AUTOSAR XML (schema 4-2-2)
package /Components
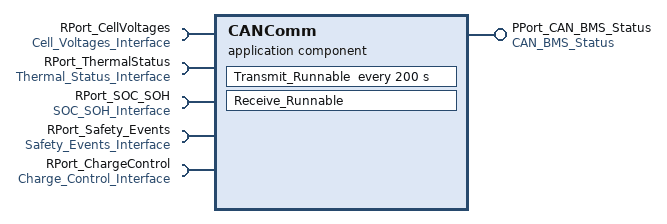
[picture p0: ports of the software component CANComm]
  application sw component type CANComm
    provide port PPort_CAN_BMS_Status: provided-interface=CAN_BMS_Status
    5 x require port:
      RPort_CellVoltages: required-interface=Cell_Voltages_Interface
      RPort_ThermalStatus: required-interface=Thermal_Status_Interface
      RPort_SOC_SOH: required-interface=SOC_SOH_Interface
      RPort_Safety_Events: required-interface=Safety_Events_Interface
      RPort_ChargeControl: required-interface=Charge_Control_Interface
    behavior CANComm_Behavior
      data received event Can_Rx_Event: start-on-event=Receive_Runnable
      timing event Can_Transmit_Timer: start-on-event=Transmit_Runnable, period=200
      runnable Transmit_Runnable: minimum-start-interval=200, symbol=RTE_CANComm_TransmitRunnable
        data-read-access:
          4 x access:
            Read_CellVoltages: accessed-variable=RPort_CellVoltages.Cell_Voltages
            Read_ThermalStatus: accessed-variable=RPort_ThermalStatus.Thermal_Status
            Read_SOC_SOH: accessed-variable=RPort_SOC_SOH.SOC_SOH
            Read_SafetyEvents: accessed-variable=RPort_Safety_Events.Safety_Event
        data-receive-point-by-arguments:
          access Rx_Placeholder_Read: accessed-variable=RPort_ChargeControl.ChargeRequest_Arg
        data-send-points:
          access Send_CAN_BMS_Summary: accessed-variable=PPort_CAN_BMS_Status.BMS_Summary
      runnable Receive_Runnable: minimum-start-interval=10, symbol=RTE_CANComm_ReceiveRunnable
        data-read-access:
          access Read_RxMessage: accessed-variable=PPort_CAN_BMS_Status.Incoming_CAN_Message
        data-receive-point-by-arguments:
          access Map_To_ChargeController: accessed-variable=RPort_ChargeControl.ChargeRequest_Arg
          access Map_To_SafetyManager: accessed-variable=RPort_Safety_Events.SafetyEvent_Arg
        data-send-points:
          access Forward_To_ChargeController: accessed-variable=RPort_ChargeControl.ChargeRequest
